# M55M1 register map
File version: 1.0
Registers are 32-bit, read-write, reset 0x0 unless marked. A register's access mark holds for its fields unless they carry their own. Offsets are from the block's base; [hi:lo] are bit positions; lines under a group give offsets from that group; {n}, {i} and the like mark numbered series; 'fields as' and 'values as' point back to an identical list.

## PMC — PMC Register Map
Base 0x40002000
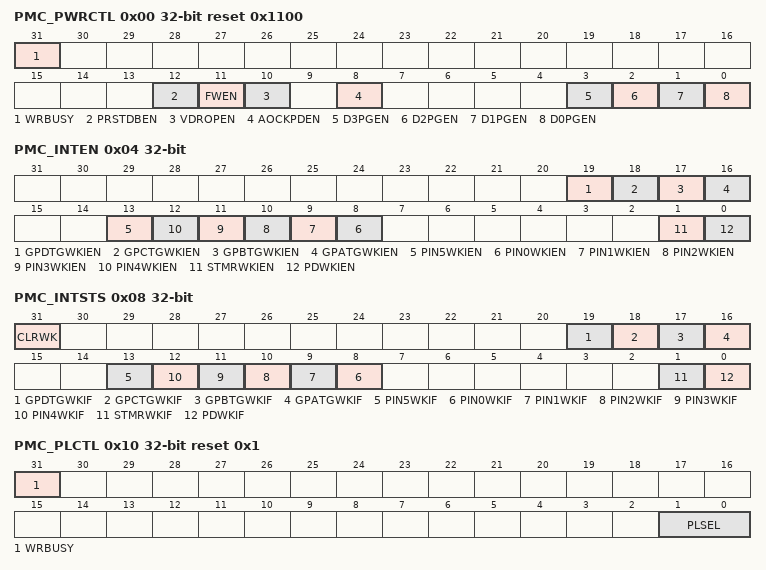
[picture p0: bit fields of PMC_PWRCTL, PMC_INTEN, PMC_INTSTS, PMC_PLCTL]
0x00 PMC_PWRCTL reset 0x1100 — System Power-down Control Register
  [31] WRBUSY ro — Write Busy Flag (Read Only). If PMC_PWRCTL is written, this bit is asserted automatically by hardware, and is de-asserted when write procedure is finished.
    0=PMC_PWRCTL register is ready for write operation; 1=PMC_PWRCTL register is busy on the last write operation. Other write operations are ignored
  [12] PRSTDBEN — Pin Reset De-Bounce Enable Bit (Write Protect). When this bit is set to 1, pin reset clock base de-bounce circuit is enable in Power-down mode. Note 1: This bit is write protected. Refer to the SYS_REGLCTL register. Note 2: This bit is not retained when D2 power is turned off. Note 3: If D2PGEN(PMC_PWRCTL[2]) is 1, The pin reset de-bounce circuit always keep disable, even if PRSTDBEN is 1. Note 4: If VDROPEN(PMC_PWRCTL[10]) is 1, The pin reset de-bounce circuit always keep disable, even if PRSTDBEN is 1.
    0=Pin reset de-bounce circuit Disable, and de-bounce time about 300ns; 1=Pin reset de-bounce circuit Enable, and de-bounce time about 32us
  [11] FWEN — Fast Wake-up Enable Bit (Write Protect). When this bit is set to 1, wake-up will be speed up, but power consumption is increase about 30uA in Power-down mode. Note 1: This bit is write protected. Refer to the SYS_REGLCTL register. Note 2: Write operation is ignored when WRBUSY is high. Note 3: This bit is not retained when D4 power is turned off.
    0=Regulator voltage auto drop function Disabled; 1=Regulator voltage auto drop function Enabled
  [10] VDROPEN — Voltage Regulator Output Drop Enable Bit (Write Protect). When this bit is set to 1, voltage regulator output drop to 0.7v in Power-down mode. Note 1: This bit is write protected. Refer to the SYS_REGLCTL register. Note 2: Write operation is ignored when WRBUSY is high. Note 3: This bit is not retained when D3 power is turned off.
    values as FWEN
  [8] AOCKPDEN — Auto Operation Mode Clock Power-down Enable (Write Protect). When this bit is set to 1, Auto Operation Mode clock Power-down mode is enabled and MIRC and HIRC keeps active till the chip enter Power-down mode. If chip in Power-down mode, HXT, HIRC48M, APLL0, APLL1 and system clock will be disabled and ignored the clock source selection. The clocks of peripheral are not controlled by Power-down mode, if the peripheral clock source is from LXT, LIRC, MIRC or HIRC. Note 1: This bit is write protected. Refer to the SYS_REGLCTL register. Note 2: This bit is not retained when D2 power is turned off.
    0=MIRC and HIRC enable in Power-down mode; 1=MIRC and HIRC disable in Power-down mode under normal circumstances, but MIRC and HIRC will be enable via a trigger from auto operation mode
  [3] D3PGEN — Power Domain 3 Power Gating Enable Bit (Write Protect). This bit control power domain 3 (Standby Power Domain) power gating function when system enter Power-down mode(CPU execute WFI/WFE instruction and SLEEPDEEP(SCR[2]) is 1). Note 1: This bit is write protected. Refer to the SYS_REGLCTL register. Note 2: Write operation is ignored when WRBUSY is high. Note 3: If D2PGEN(PMC_PWRCTL[2]) is 0, The power domain 3 always keep supply, even if D3PGEN is 1. Note 4: This bit is not retained when D4 power is turned off.
    0=Power domain 3 keep supply; 1=Power domain 3 stop supply
  [2] D2PGEN — Power Domain 2 Power Gating Enable Bit (Write Protect). This bit control power domain 2 (Low Power Domain) power gating function when system enter Power-down mode(CPU execute WFI/WFE instruction and SLEEPDEEP(SCR[2]) is 1). Note 1: This bit is write protected. Refer to the SYS_REGLCTL register. Note 2: Write operation is ignored when WRBUSY is high. Note 3: If D1PGEN(PMC_PWRCTL[1]) is 0, The power domain 2 always keep supply, even if D2PGEN is 1. Note 4: This bit is not retained when D4 power is turned off.
    0=Power domain 2 keep supply; 1=Power domain 2 stop supply
  [1] D1PGEN — Power Domain 1 Power Gating Enable Bit (Write Protect). This bit control power domain 1 (Base Domain) power gating function when system enter Power-down mode(CPU execute WFI/WFE instruction and SLEEPDEEP(SCR[2]) is 1). Note 1: This bit is write protected. Refer to the SYS_REGLCTL register. Note 2: Write operation is ignored when WRBUSY is high. Note 3: If D0PGEN(PMC_PWRCTL[0]) is 0, The power domain 1 always keep supply, even if D1PGEN is 1. Note 4: This bit is not retained when D4 power is turned off.
    0=Power domain 1 keep supply; 1=Power domain 1 stop supply
  [0] D0PGEN — Power Domain 0 Power Gating Enable Bit (Write Protect). This bit control power domain 0 (Performance Domain) power gating function when system enter Power-down mode(CPU execute WFI/WFE instruction and SLEEPDEEP(SCR[2]) is 1). Note 1: This bit is write protected. Refer to the SYS_REGLCTL register. Note 2: Write operation is ignored when WRBUSY is high. Note 3: This bit is not retained when D4 power is turned off.
    0=Power domain 0 keep supply; 1=Power domain 0 stop supply
0x04 PMC_INTEN — PMC Interrupt Enable Register
  [19] GPDTGWKIEN — GPD Trigger Wake-up Interrupt Enable Bit (Write Protect). Note 1: The PMC interrupt will occur when both GPDTGWKIF(PMC_INTSTS[19] and GPDTGWKIEN(PMC_INTEN[19]) are 1. Note 2: This bit is write protected. Refer to the SYS_REGLCTL register. Note 3: This bit is not retained when D3 power is turned off.
    0=GPD triggrer wake-up interrupt disabled; 1=GPD triggrer wake-up interrupt enabled
  [18] GPCTGWKIEN — GPC Trigger Wake-up Interrupt Enable Bit (Write Protect). Note 1: The PMC interrupt will occur when both GPCTGWKIF(PMC_INTSTS[18] and GPCTGWKIEN(PMC_INTEN[18]) are 1. Note 2: This bit is write protected. Refer to the SYS_REGLCTL register. Note 3: This bit is not retained when D3 power is turned off.
    0=GPC triggrer wake-up interrupt disabled; 1=GPC triggrer wake-up interrupt enabled
  [17] GPBTGWKIEN — GPB Trigger Wake-up Interrupt Enable Bit (Write Protect). Note 1: The PMC interrupt will occur when both GPBTGWKIF(PMC_INTSTS[17] and GPBTGWKIEN(PMC_INTEN[17]) are 1. Note 2: This bit is write protected. Refer to the SYS_REGLCTL register. Note 3: This bit is not retained when D3 power is turned off.
    0=GPB triggrer wake-up interrupt disabled; 1=GPB triggrer wake-up interrupt enabled
  [16] GPATGWKIEN — GPA Trigger Wake-up Interrupt Enable Bit (Write Protect). Note 1: The PMC interrupt will occur when both GPATGWKIF(PMC_INTSTS[16] and GPATGWKIEN(PMC_INTEN[16]) are 1. Note 2: This bit is write protected. Refer to the SYS_REGLCTL register. Note 3: This bit is not retained when D3 power is turned off.
    0=GPA triggrer wake-up interrupt disabled; 1=GPA triggrer wake-up interrupt enabled
  [13] PIN5WKIEN — Pin 5 Wake-up Interrupt Enable Bit (Write Protect). Note 1: The PMC interrupt will occur when both PIN4WKIF(PMC_INTSTS[13] and PIN4WKIEN(PMC_INTEN[13]) are 1. Note 2: This bit is write protected. Refer to the SYS_REGLCTL register. Note 3: This bit is not retained when D4 power is turned off.
    0=Pin 5 wake-up interrupt disabled; 1=Pin 5 wake-up interrupt enabled
  [n+8] PIN{n}WKIEN (n=0..4) — Pin {n} Wake-up Interrupt Enable Bit (Write Protect). Note 1: The PMC interrupt will occur when both PIN{n}WKIF(PMC_INTSTS[{n+8}] and PIN{n}WKIEN(PMC_INTEN[{n+8}]) are 1. Note 2: This bit is write protected. Refer to the SYS_REGLCTL register. Note 3: This bit is not retained when D4 power is turned off.
    0=Pin {n} wake-up interrupt disabled; 1=Pin {n} wake-up interrupt enabled
  [1] STMRWKIEN — Standby Timer Wake-up Interrupt Enable Bit (Write Protect). Note 1: The PMC interrupt will occur when both STMRWKIF(PMC_INTSTS[1] and STMRWKIEN(PMC_INTEN[1]) are 1. Note 2: This bit is write protected. Refer to the SYS_REGLCTL register. Note 3: This bit is not retained when D4 power is turned off.
    0=High Voltage Timer wake-up interrupt disable; 1=High Voltage Timer wake-up interrupt enabled
  [0] PDWKIEN — Power-down Mode Wake-up Interrupt Enable Bit (Write Protect). Note 1: The PMC interrupt will occur when both PDWKIF(PMC_INTSTS[0] and PDWKIEN(PMC_INTEN[0]) are 1. Note 2: This bit is write protected. Refer to the SYS_REGLCTL register. Note 3: This bit is not retained when D4 power is turned off.
    0=Power-down mode wake-up interrupt Disabled; 1=Power-down mode wake-up interrupt Enabled
0x08 PMC_INTSTS — PMC Interrupt Status Register
  [31] CLRWK — Clear Wake-up Flag. Clearing the Wake-up flag is not timely. Flags in PMC_INTSTS will not be immediately cleared in the next cycle when CLRWK written to 1. Note 1: This bit is auto cleared by hardware.
    0=No clear; 1=Clear all wake-up flags
  [19] GPDTGWKIF — GPC Trigger Wake-up Interrupt Status. The flag is set if GPD trigger wake-up event occurred in Power-down mode. Note 1: The PMC interrupt will occur when both GPDTGWKIF(PMC_INTSTS[19] and GPDTGWKIEN(PMC_INTEN[19]) are 1. Note 2: This bit is not retained when D0 power is turned off.
  [18] GPCTGWKIF — GPC Trigger Wake-up Interrupt Status. The flag is set if GPC trigger wake-up event occurred in Power-down mode. Note 1: The PMC interrupt will occur when both GPCTGWKIF(PMC_INTSTS[18] and GPCTGWKIEN(PMC_INTEN[18]) are 1. Note 2: This bit is not retained when D0 power is turned off.
  [17] GPBTGWKIF — GPB Trigger Wake-up Interrupt Status. The flag is set if GPB trigger wake-up event occurred in Power-down mode. Note 1: The PMC interrupt will occur when both GPBTGWKIF(PMC_INTSTS[17] and GPBTGWKIEN(PMC_INTEN[17]) are 1. Note 2: This bit is not retained when D0 power is turned off.
  [16] GPATGWKIF — GPA Trigger Wake-up Interrupt Status. The flag is set if GPA trigger wake-up event occurred in Power-down mode. Note 1: The PMC interrupt will occur when both GPATGWKIF(PMC_INTSTS[16] and GPATGWKIEN(PMC_INTEN[16]) are 1. Note 2: This bit is not retained when D0 power is turned off.
  [13] PIN5WKIF — Pin 5 Wake-up Interrupt Status. The flag is set if Pin 5 wake-up event occurred in Power-down mode. Note 1: The PMC interrupt will occur when both PIN4WKIF(PMC_INTSTS[13] and PIN4WKIEN(PMC_INTEN[13]) are 1. Note 2: This bit is not retained when D0 power is turned off.
  [n+8] PIN{n}WKIF (n=0..4) — Pin {n} Wake-up Interrupt Status. The flag is set if Pin {n} wake-up event occurred in Power-down mode. Note 1: The PMC interrupt will occur when both PIN{n}WKIF(PMC_INTSTS[{n+8}] and PIN{n}WKIEN(PMC_INTEN[{n+8}]) are 1. Note 2: This bit is not retained when D0 power is turned off.
  [1] STMRWKIF — Standby Timer Wake-up Interrupt Status. The flag is set if stadnby timer wake-up event occurred in Power-down mode. Note 1: The PMC interrupt will occur when both STMRWKIF(PMC_INTSTS[1] and STMRWKIEN(PMC_INTEN[1]) are 1. Note 2: This bit is not retained when D0 power is turned off.
  [0] PDWKIF — Power-down Mode Wake-up Interrupt Status. Set by 'Power-down wake-up event', it indicates that resume from Power-down mode. The flag is set if any wake-up source occurred. Refer Power Modes and Wake-up Sources chapter. Note 1: The PMC interrupt will occur when both PDWKIF(PMC_INTSTS[0] and PDWKIEN(PMC_INTEN[0]) are 1. Note 2: This bit is not retained when D0 power is turned off.
0x10 PMC_PLCTL reset 0x1 — Power Level Control Register
  [31] WRBUSY ro — Write Busy Flag (Read Only). If PMC_PLCTL is written, this bit is asserted automatically by hardware, and is de-asserted when write procedure is finished.
    0=PMC_PLCTL register is ready for write operation; 1=PMC_PLCTL register is busy on the last write operation. Other write operations are ignored
  [1:0] PLSEL — Power Level Select (Write Protect). Note 1: These bits are write protected. Refer to the SYS_REGLCTL register. Note 2: Write operation is ignored when WRBUSY is high. Note 3: These bits are not retained when D3 power is turned off.
    0=Set to Power level 0 (PL0); 1=Set to Power level 1 (PL1). (default)
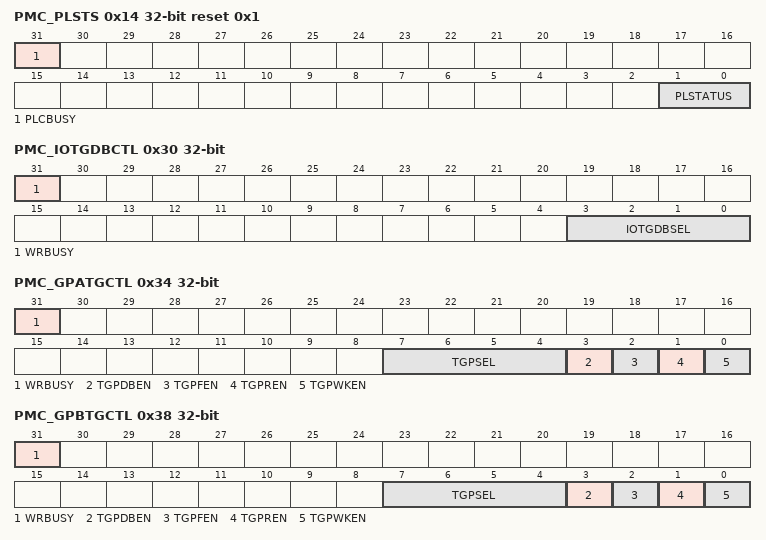
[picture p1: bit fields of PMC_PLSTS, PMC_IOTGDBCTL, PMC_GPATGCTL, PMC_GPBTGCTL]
0x14 PMC_PLSTS reset 0x1 — Power Level Status Register
  [31] PLCBUSY ro — Power Level Change Busy Bit (Read Only). This bit is set by hardware when power level is changing. After power level change is completed, this bit will be cleared automatically by hardware.
    0=Power level change is completed; 1=Power level change is ongoing
  [1:0] PLSTATUS ro — Power Level Status (Read Only). This bit field reflect the current power level.
    0=Power level is PL0; 1=Power level is PL1
0x20 PMC_IOSHCTL — GPIO Status Hold Control Register
  [0] IOHR — GPIO Hold Release. Note 1: This bit is auto cleared by hardware. Note 2: This bit is not retained when D0 power is turned off.
0x28 PMC_BATLDCTL — Battery Loss Detector Control Register
  [0] BATLDEN — Battery Loss Detector Enable Bit (Write Protect). Note 1: This bit is write protected. Refer to the SYS_REGLCTL register. Note 2: This bit is not retained when D3 power is turned off.
    0=Battery Loss Detector Disabled; 1=Battery Loss Detector Enabled
0x30 PMC_IOTGDBCTL — GPIO Trigger De-bounce Control Register
  [31] WRBUSY ro — Write Busy Flag (Read Only). If PMC_IOTGDBCTL is written, this bit is asserted automatically by hardware, and is de-asserted when write procedure is finished.
    0=PMC_ IOTGDBCTL register is ready for write operation; 1=PMC_ IOTGDBCTL register is busy on the last write operation. Other write operations are ignored
  [3:0] IOTGDBSEL — GPIO Trigger Pin De-bounce Sampling Cycle Selection. Note 1: De-bounce counter clock source is the 32 kHz internal low speed RC oscillator (LIRC). Note 2: Write operation is ignored when WRBUSY is high. Note 3: These bits are not retained when D3 power is turned off.
    0=Sample GPIO input once per 1 clock; 1=Sample GPIO input once per 2 clocks; 2=Sample GPIO input once per 4 clocks; 3=Sample GPIO input once per 8 clocks; 4=Sample GPIO input once per 16 clocks; 5=Sample GPIO input once per 32 clocks; 6=Sample GPIO input once per 64 clocks; 7=Sample GPIO input once per 128 clocks; 8=Sample GPIO input once per 256 clocks; 9=Sample GPIO input once per 2*256 clocks; 10=Sample GPIO input once per 4*256 clocks; 11=Sample GPIO input once per 8*256 clocks; 12=Sample GPIO input once per 16*256 clocks; 13=Sample GPIO input once per 32*256 clocks; 14=Sample GPIO input once per 64*256 clocks; 15=Sample GPIO input once per 128*256 clocks
0x34 PMC_GPATGCTL — GPA Trigger Control Register
  [31] WRBUSY ro — Write Busy Flag (Read Only). If PMC_GPATGCTL is written, this bit is asserted automatically by hardware, and is de-asserted when write procedure is finished.
    0=PMC_ GPATGCTL register is ready for write operation; 1=PMC_ GPATGCTL register is busy on the last write operation. Other write operations are ignored
  [7:4] TGPSEL — GPA Trigger Pin Select. Note: These bits are not retained when D3 power is turned off.
    0=GPA.0 trigger function Enabled; 1=GPA.1 trigger function Enabled; 2=GPA.2 trigger function Enabled; 3=GPA.3 trigger function Enabled; 4=GPA.4 trigger function Enabled; 5=GPA.5 trigger function Enabled; 6=GPA.6 trigger function Enabled; 7=GPA.7 trigger function Enabled; 8=GPA.8 trigger function Enabled; 9=GPA.9 trigger function Enabled; 10=GPA.10 trigger function Enabled; 11=GPA.11 trigger function Enabled; 12=GPA.12 trigger function Enabled; 13=GPA.13 trigger function Enabled; 14=GPA.14 trigger function Enabled; 15=GPA.15 trigger function Enabled
  [3] TGPDBEN — GPA Trigger Pin Input Signal De-bounce Enable Bit. The DBEN bit is used to enable the de-bounce function for each corresponding I/O. If the input signal pulse width cannot be sampled by continuous two de-bounce sample cycle, the input signal transition is seen as the signal bounce and will not trigger and wake-up.The de-bounce clock source is the 32 kHz internal low speed RC oscillator (LIRC). Note 1: The 32 kHz internal low speed RC oscillator (LIRC) will automatically be enabled if TGPDBEN is 1. Note 2: Write operation is ignored when WRBUSY is high. Note 3: This bit is not retained when D3 power is turned off.
    0=Trigger pin De-bounce function Disabled; 1=Trigger pin De-bounce function Enabled
  [2] TGPFEN — GPA Trigge Pin Falling Edge Enable Bit. Note 1: Write operation is ignored when WRBUSY is high. Note 2: This bit is not retained when D3 power is turned off.
    0=GPA group trigger pin falling edge trigger function Disabled; 1=GPA group trigger pin falling edge trigger function Enabled
  [1] TGPREN — GPA Trigger Pin Rising Edge Enable Bit. Note 1: Write operation is ignored when WRBUSY is high. Note 2: This bit is not retained when D3 power is turned off.
    0=GPA group trigger pin rising edge trigger function Disabled; 1=GPA group trigger pin rising edge trigger function Enabled
  [0] TGPWKEN — GPA Trigger Pin Wake-up Enable Bit. Note 1: The GPA Trigger Pin wake-up is always enable when D2PGEN(PMC_PWRCTL[2] is 1. Note 2: This bit is not retained when D2 power is turned off.
    0=GPA group trigger pin wake-up chip Disabled, trigger ip Enabled; 1=GPA group trigger pin wake-up chip Enabled, trigger ip Enabled
0x38 PMC_GPBTGCTL — GPB Trigger Control Register
  [31] WRBUSY ro — Write Busy Flag (Read Only). If PMC_GPBTGCTL is written, this bit is asserted automatically by hardware, and is de-asserted when write procedure is finished.
    0=PMC_ GPBTGCTL register is ready for write operation; 1=PMC_ GPBTGCTL register is busy on the last write operation. Other write operations are ignored
  [7:4] TGPSEL — GPB Trigger Pin Select. Note: These bits are not retained when D3 power is turned off.
    0=GPB.0 trigger function Enabled; 1=GPB.1 trigger function Enabled; 2=GPB.2 trigger function Enabled; 3=GPB.3 trigger function Enabled; 4=GPB.4 trigger function Enabled; 5=GPB.5 trigger function Enabled; 6=GPB.6 trigger function Enabled; 7=GPB.7 trigger function Enabled; 8=GPB.8 trigger function Enabled; 9=GPB.9 trigger function Enabled; 10=GPB.10 trigger function Enabled; 11=GPB.11 trigger function Enabled; 12=GPB.12 trigger function Enabled; 13=GPB.13 trigger function Enabled; 14=GPB.14 trigger function Enabled; 15=GPB.15 trigger function Enabled
  [3] TGPDBEN — GPB Trigger Pin Input Signal De-bounce Enable Bit. The DBEN bit is used to enable the de-bounce function for each corresponding I/O. If the input signal pulse width cannot be sampled by continuous two de-bounce sample cycle, the input signal transition is seen as the signal bounce and will not trigger and wake-up.The de-bounce clock source is the 32 kHz internal low speed RC oscillator (LIRC). Note 1: The 32 kHz internal low speed RC oscillator (LIRC) will automatically be enabled if TGPDBEN is 1. Note 2: Write operation is ignored when WRBUSY is high. Note 3: This bit is not retained when D3 power is turned off.
    values as PMC_GPATGCTL.TGPDBEN
  [2] TGPFEN — GPB Trigge Pin Falling Edge Enable Bit. Note: This bit is not retained when D3 power is turned off.
    0=GPB group trigger pin falling edge trigger function Disabled; 1=GPB group trigger pin falling edge trigger function Enabled
  [1] TGPREN — GPB Trigger Pin Rising Edge Enable Bit. Note 1: Write operation is ignored when WRBUSY is high. Note 2: This bit is not retained when D3 power is turned off.
    0=GPB group trigger pin rising edge trigger function Disabled; 1=GPB group trigger pin rising edge trigger function Enabled
  [0] TGPWKEN — GPB Trigger Pin Wake-up Enable Bit. Note 1: The GPB Trigger Pin wake-up is always enable when D2PGEN(PMC_PWRCTL[2] is 1. Note 2: This bit is not retained when D2 power is turned off.
    0=GPB group trigger pin wake-up chip Disabled, trigger ip Enabled; 1=GPB group trigger pin wake-up chip Enabled, trigger ip Enabled
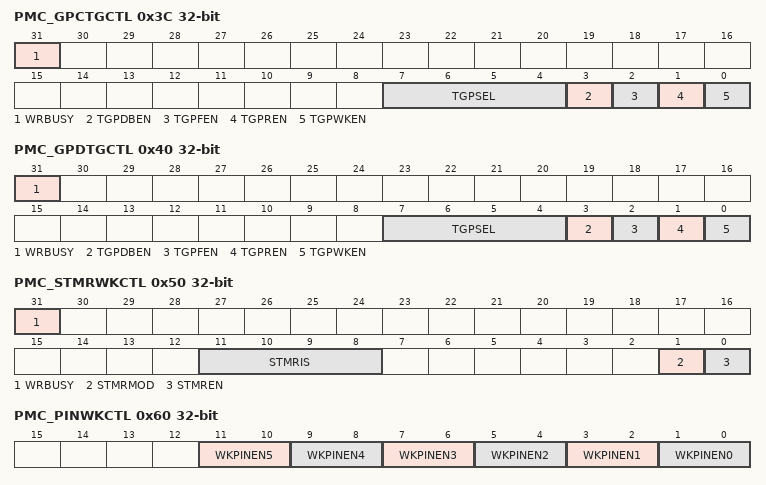
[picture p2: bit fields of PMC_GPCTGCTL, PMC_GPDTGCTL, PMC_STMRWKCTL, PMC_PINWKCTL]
0x3C PMC_GPCTGCTL — GPC Trigger Control Register
  [31] WRBUSY ro — Write Busy Flag (Read Only). If PMC_GPCTGCTL is written, this bit is asserted automatically by hardware, and is de-asserted when write procedure is finished.
    0=PMC_ GPCTGCTL register is ready for write operation; 1=PMC_ GPCTGCTL register is busy on the last write operation. Other write operations are ignored
  [7:4] TGPSEL — GPC Trigger Pin Select. Note: These bits are not retained when D3 power is turned off.
    0=GPC.0 trigger function Enabled; 1=GPC.1 trigger function Enabled; 2=GPC.2 trigger function Enabled; 3=GPC.3 trigger function Enabled; 4=GPC.4 trigger function Enabled; 5=GPC.5 trigger function Enabled; 6=GPC.6 trigger function Enabled; 7=GPC.7 trigger function Enabled; 8=GPC.8 trigger function Enabled; 9=GPC.9 trigger function Enabled; 10=GPC.10 trigger function Enabled; 11=GPC.11 trigger function Enabled; 12=GPC.12 trigger function Enabled; 13=GPC.13 trigger function Enabled; 14=GPC.14 trigger function Enabled
  [3] TGPDBEN — GPC Trigger Pin Input Signal De-bounce Enable Bit. The TGPDBEN bit is used to enable the de-bounce function for each corresponding I/O. If the input signal pulse width cannot be sampled by continuous two de-bounce sample cycle, the input signal transition is seen as the signal bounce and will not trigger and wake-up.The de-bounce clock source is the 32 kHz internal low speed RC oscillator (LIRC). Note 1: The 32 kHz internal low speed RC oscillator (LIRC) will automatically be enabled if TGPDBEN is 1. Note 2: Write operation is ignored when WRBUSY is high. Note 3: This bit is not retained when D3 power is turned off.
    values as PMC_GPATGCTL.TGPDBEN
  [2] TGPFEN — GPC Trigge Pin Falling Edge Enable Bit. Note 1: Write operation is ignored when WRBUSY is high. Note 2: This bit is not retained when D3 power is turned off.
    0=GPC group trigger pin falling edge trigger function Disabled; 1=GPC group trigger pin falling edge trigger function Enabled
  [1] TGPREN — GPC Trigger Pin Rising Edge Enable Bit. Note 1: Write operation is ignored when WRBUSY is high. Note 2: This bit is not retained when D3 power is turned off.
    0=GPC group trigger pin rising edge trigger function Disabled; 1=GPC group trigger pin rising edge trigger function Enabled
  [0] TGPWKEN — GPC Trigger Pin Wake-up Enable Bit. Note 1: The GPC Trigger Pin wake-up is always enable when D2PGEN(PMC_PWRCTL[2] is 1. Note 2: This bit is not retained when D2 power is turned off.
    0=GPC group trigger pin wake-up chip Disabled, trigger ip Enabled; 1=GPC group trigger pin wake-up chip Enabled, trigger ip Enabled
0x40 PMC_GPDTGCTL — GPD Trigger Control Register
  [31] WRBUSY ro — Write Busy Flag (Read Only). If PMC_GPDTGCTL is written, this bit is asserted automatically by hardware, and is de-asserted when write procedure is finished.
    0=PMC_ GPDTGCTL register is ready for write operation; 1=PMC_ GPDTGCTL register is busy on the last write operation. Other write operations are ignored
  [7:4] TGPSEL — GPD Trigger Pin Select. Note: These bits are not retained when D3 power is turned off.
    0=GPD.0 trigger function Enabled; 1=GPD.1 trigger function Enabled; 2=GPD.2 trigger function Enabled; 3=GPD.3 trigger function Enabled; 4=GPD.4 trigger function Enabled; 5=GPD.5 trigger function Enabled; 6=GPD.6 trigger function Enabled; 7=GPD.7 trigger function Enabled; 8=GPD.8 trigger function Enabled; 9=GPD.9 trigger function Enabled; 10=GPD.10 trigger function Enabled; 11=GPD.11 trigger function Enabled; 12=GPD.12 trigger function Enabled; 13=GPD.13 trigger function Enabled; 14=GPD.14 trigger function Enabled
  [3] TGPDBEN — GPD Trigger Pin Input Signal De-bounce Enable Bit. The DBEN bit is used to enable the de-bounce function for each corresponding I/O. If the input signal pulse width cannot be sampled by continuous two de-bounce sample cycle, the input signal transition is seen as the signal bounce and will not trigger and wake-up.The de-bounce clock source is the 32 kHz internal low speed RC oscillator (LIRC). Note 1: The 32 kHz internal low speed RC oscillator (LIRC) will automatically be enabled if TGPDBEN is 1. Note 2: Write operation is ignored when WRBUSY is high. Note 3: This bit is not retained when D3 power is turned off.
    values as PMC_GPATGCTL.TGPDBEN
  [2] TGPFEN — GPD Trigge Pin Falling Edge Enable Bit. Note 1: Write operation is ignored when WRBUSY is high. Note 2: This bit is not retained when D3 power is turned off.
    0=GPD group trigger pin falling edge trigger function Disabled; 1=GPD group trigger pin falling edge trigger function Enabled
  [1] TGPREN — GPD Trigger Pin Rising Edge Enable Bit. Note 1: Write operation is ignored when WRBUSY is high. Note 2: This bit is not retained when D3 power is turned off.
    0=GPD group trigger pin rising edge trigger function Disabled; 1=GPD group trigger pin rising edge trigger function Enabled
  [0] TGPWKEN — GPD Trigger Pin Wake-up Enable Bit. Note 1: The GPD Trigger Pin wake-up is always enable when D2PGEN(PMC_PWRCTL[2] is 1. Note 2: This bit is not retained when D2 power is turned off.
    0=GPD group trigger pin wake-up chip Disabled, trigger ip Enabled; 1=GPD group trigger pin wake-up chip Enabled, trigger ip Enabled
0x50 PMC_STMRWKCTL — Standby Timer Wake-up Control Register
  [31] WRBUSY ro — Write Busy Flag (Read Only). If PMC_STMRWKCTL is written, this bit is asserted automatically by hardware, and is de-asserted when write procedure is finished.
    0=PMC_ STMRWKCTL register is ready for write operation; 1=PMC_ STMRWKCTL register is busy on the last write operation. Other write operations are ignored
  [11:8] STMRIS — Stadnby Timer Time-out Interval Select (Write Protect). These bits control standby timer time-out interval when chip at Power-down mode. Note 1: These bits are write protected. Refer to the SYS_REGLCTL register. Note 2: Write operation is ignored when WRBUSY is high. Note 3: These bits are not retained when D4 power is turned off.
    0=Time-out interval is 512 LIRC clocks (16ms); 1=Time-out interval is 1024 LIRC clocks (32ms); 2=Time-out interval is 2048 LIRC clocks (64ms); 3=Time-out interval is 4096 LIRC clocks (128ms); 4=Time-out interval is 8192 LIRC clocks (256ms); 5=Time-out interval is 16384 LIRC clocks (512ms); 6=Time-out interval is 32768 LIRC clocks (1024ms); 7=Time-out interval is 65536 LIRC clocks (2048ms); 8=Time-out interval is 131072 LIRC clocks (4096ms); 9=Time-out interval is 262144 LIRC clocks (8192ms); 10=Time-out interval is 524288 LIRC clocks (16384ms); 11=Time-out interval is 1048576 LIRC clocks (32768ms); 12=Time-out interval is 2097152 LIRC clocks (65536ms); 13=Time-out interval is 4194304 LIRC clocks (131072ms)
  [1] STMRMOD — Standby Timer Mode (Write Protect). Note 1: This bit is write protected. Refer to the SYS_REGLCTL register. Note 2: Write operation is ignored when WRBUSY is high. Note 3: This bit is not retained when D4 power is turned off.
    0=Standby timer start when enter any of Power-down mode ( except CPU idle mode); 1=Standby timer start immedially when STMREN (PMC_STMRWKCTL[0]) =1
  [0] STMREN — Standby Timer Enable Bit (Write Protect). Note 1: This bit is write protected. Refer to the SYS_REGLCTL register. Note 2: Write operation is ignored when WRBUSY is high. Note 3: This bit is not retained when D4 power is turned off.
    0=Standby timer disabled; 1=Standby timer Enabled
0x60 PMC_PINWKCTL — Pin Wake-up Control Register
  [all] fields
    0=Wake-up pin disable; 1=Wake-up pin rising edge enabled; 2=Wake-up pin falling edge enabled; 3=Wake-up pin both edge enabled
  [11:10] WKPINEN5 — Wake-up Pin5 Enable Bit (Write Protect). This is control register for GPA.12 to wake-up pin. Note 1: These bits are write protected. Refer to the SYS_REGLCTL register. Note 2: These bits are not retained when D4 power is turned off.
  [9:8] WKPINEN4 — Wake-up Pin4 Enable Bit (Write Protect). This is control register for GPF.6 to wake-up pin. Note 1: These bits are write protected. Refer to the SYS_REGLCTL register. Note 2: These bits are not retained when D4 power is turned off. Note 3: Setting IOCTLSEL(RTC_LXTCTL[8]) to avoid GPF6 unexpected falling edge.
  [7:6] WKPINEN3 — Wake-up Pin3 Enable Bit (Write Protect). This is control register for GPB.12 to wake-up pin. Note 1: These bits are write protected. Refer to the SYS_REGLCTL register. Note 2: These bits are not retained when D4 power is turned off.
  [5:4] WKPINEN2 — Wake-up Pin2 Enable Bit (Write Protect). This is control register for GPB.2 to wake-up pin. Note 1: These bits are write protected. Refer to the SYS_REGLCTL register. Note 2: These bits are not retained when D4 power is turned off.
  [3:2] WKPINEN1 — Wake-up Pin1 Enable Bit (Write Protect). This is control register for GPB.0 to wake-up pin. Note 1: These bits are write protected. Refer to the SYS_REGLCTL register. Note 2: These bits are not retained when D4 power is turned off.
  [1:0] WKPINEN0 — Wake-up Pin0 Enable Bit (Write Protect). This is control register for GPC.0 to wake-up pin. Note 1: These bits are write protected. Refer to the SYS_REGLCTL register. Note 2: These bits are not retained when D4 power is turned off.
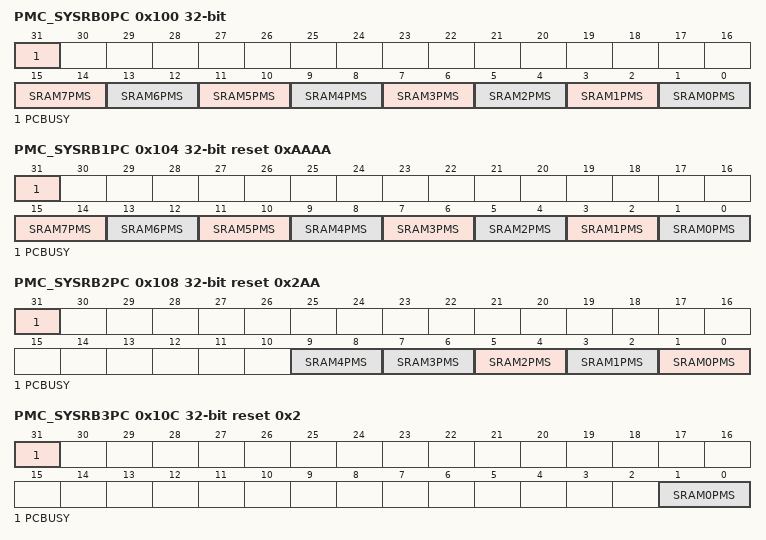
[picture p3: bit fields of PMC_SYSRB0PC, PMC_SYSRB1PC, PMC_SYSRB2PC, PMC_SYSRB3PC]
0x100 PMC_SYSRB0PC — System SRAM Bank 0 Power Mode Control Register
  [31] PCBUSY ro — Power Changing Busy Flag (Read Only). If PMC_SYSRB0PC is written, this bit is asserted automatically by hardware, and is de-asserted when SRAM power change procedure is finished. set to power shut down mode by hardware. Note 1: This bit is not retained when D3 power is turned off.
    0=System SRAM bank 0 power change finished; 1=System SRAM bank 0 power changing. The PMC_SYSRB0PC write operations are ignored
  [2n+1:2n] SRAM{n}PMS (n=0..7) — System SRAM{n} In Bank0 Power Mode Select (Write Protect). This field can control SRAM{n} in bank0 (64k) power mode for range {0x2010+n}_0000 - {0x2010+n}_FFFF. Note 1: Power shut down mode can get least leakage, but don't guarantee the retention of SRAM data. Note 2: This bit is write protected. Refer to the SYS_REGLCTL register. Note 3: Write operation is ignored when PCBUSY is 1. Note 4: These bits are not retained when D3 power is turned off.
    0=System SRAM{n} in bank0 is normal mode; 1=System SRAM{n} in bank0 is retention mode; 2=System SRAM{n} in bank0 is power shut down mode
0x104 PMC_SYSRB1PC reset 0xAAAA — System SRAM Bank 1 Power Mode Control Register
  [31] PCBUSY ro — Power Changing Busy Flag (Read Only). If PMC_SYSRB1PC is written, this bit is asserted automatically by hardware, and is de-asserted when SRAM power change procedure is finished. Note 1: This bit is not retained when D0 power is turned off.
    0=System SRAM bank 1 power change finished; 1=System SRAM bank 1 power changing. The PMC_SYSRB1PC write operations are ignored
  [2n+1:2n] SRAM{n}PMS (n=0..7) — System SRAM{n} In Bank1 Power Mode Select (Write Protect). This field can control SRAM{n} in bank1 (64k) power mode for range {0x2018+n}_0000 - {0x2018+n}_FFFF. Note 1: Power shut down mode can get least leakage, but don't guarantee the retention of SRAM data. Note 2: This bit is write protected. Refer to the SYS_REGLCTL register. Note 3: Write operation is ignored when PCBUSY is 1. Note 4: If system enter Power-down mode and D0PGEN(PMC_PWRCTL[0]) is set to 1, This SRAM is auto set to power shut down mode by hardware. Note 5: These bits are not retained when D0 power is turned off.
    0=System SRAM{n} in bank1 is normal mode; 1=System SRAM{n} in bank1 is retention mode; 2=System SRAM{n} in bank1 is power shut down mode
0x108 PMC_SYSRB2PC reset 0x2AA — System SRAM Bank 2 Power Mode Control Register
  [31] PCBUSY ro — Power Changing Busy Flag (Read Only). If PMC_SYSRB2PC is written, this bit is asserted automatically by hardware, and is de-asserted when SRAM power change procedure is finished. Note: This bit is not retained when D0 power is turned off.
    0=System SRAM bank 2 power change finished; 1=System SRAM bank 2 power changing. The PMC_SYSRB2PC write operations are ignored
  [9:8] SRAM4PMS — System SRAM4 In Bank2 Power Mode Select (Write Protect). This field can control SRAM2 in bank1 (64k) power mode for range 0x2024_0000 - 0x2024_FFFF. Note 1: Power shut down mode can get least leakage, but don't guarantee the retention of SRAM data. Note 2: This bit is write protected. Refer to the SYS_REGLCTL register. Note 3: Write operation is ignored when PCBUSY is 1. Note 4: If system enter Power-down mode and D0PGEN(PMC_PWRCTL[0]) is set to 1, This SRAM is auto set to power shut down mode by hardware. Note 5: These bits are not retained when D0 power is turned off.
    0=System SRAM4 in bank2 is normal mode; 1=System SRAM4 in bank2 is retention mode; 2=System SRAM4 in bank2 is power shut down mode
  [2n+1:2n] SRAM{n}PMS (n=0..3) — System SRAM{n} In Bank2 Power Mode Select (Write Protect). This field can control SRAM{n} in bank2 (64k) power mode for range {0x2020+n}_0000 - {0x2020+n}_FFFF. Note 1: Power shut down mode can get least leakage, but don't guarantee the retention of SRAM data. Note 2: This bit is write protected. Refer to the SYS_REGLCTL register. Note 3: Write operation is ignored when PCBUSY is 1. Note 4: If system enter Power-down mode and D0PGEN(PMC_PWRCTL[0]) is set to 1, This SRAM is auto set to power shut down mode by hardware. Note 5: These bits are not retained when D0 power is turned off.
    0=System SRAM{n} in bank2 is normal mode; 1=System SRAM{n} in bank2 is retention mode; 2=System SRAM{n} in bank2 is power shut down mode
0x10C PMC_SYSRB3PC reset 0x2 — System SRAM Bank 3 Power Mode Control Register
  [31] PCBUSY ro — Power Changing Busy Flag (Read Only). If PMC_SYSRB3PC is written, this bit is asserted automatically by hardware, and is de-asserted when SRAM power change procedure is finished. Note 1: This bit is not retained when D1 power is turned off.
    0=System SRAM bank 3 power change finished; 1=System SRAM bank 3 power changing. The PMC_SYSRB0PC write operations are ignored
  [1:0] SRAM0PMS — System SRAM0 In Bank3 Power Mode Select (Write Protect). This field can control SRAM0 in bank3 (8k) power mode for range 0x2030_0000 - 0x2030_1FFF. Note 1: Power shut down mode can get least leakage, but don't guarantee the retention of SRAM data. Note 2: This bit is write protected. Refer to the SYS_REGLCTL register. Note 3: Write operation is ignored when PCBUSY is 1. Note 4: If system enter Power-down mode and D1PGEN(PMC_PWRCTL[1]) is set to 1, This SRAM is auto set to power shut down mode by hardware. Note 5: These bits are not retained when D1 power is turned off.
    0=System SRAM0 in bank3 is normal mode; 1=System SRAM0 in bank3 is retention mode; 2=System SRAM0 in bank3 is power shut down mode
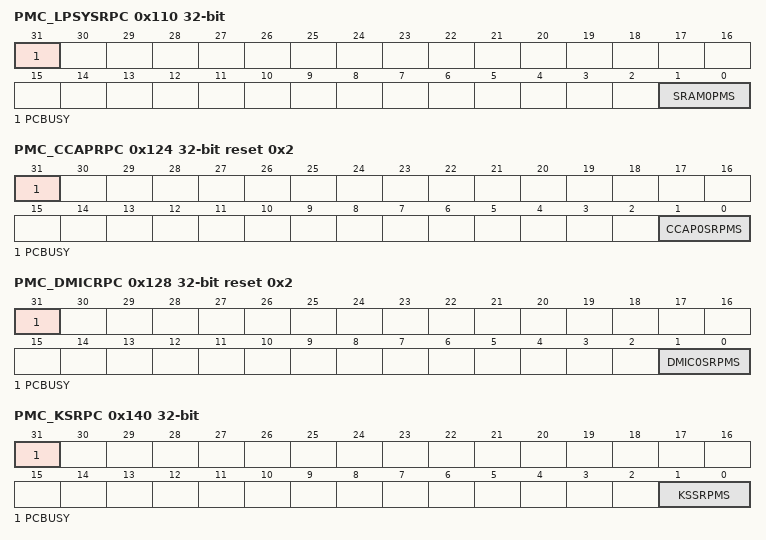
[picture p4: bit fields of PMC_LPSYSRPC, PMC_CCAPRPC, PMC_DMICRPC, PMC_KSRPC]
0x110 PMC_LPSYSRPC — Low Power Domain System SRAM Power Mode Control Register
  [31] PCBUSY ro — Power Changing Busy Flag (Read Only). If PMC_LPSYSRPC is written, this bit is asserted automatically by hardware, and is de-asserted when SRAM power change procedure is finished. Note 1: This bit is not retained when D3 power is turned off.
    0=Low power domain SRAM bank 3 power change finished; 1=Low power domain power changing. The PMC_SYSLPRPC write operations are ignored
  [1:0] SRAM0PMS — Low Power Domain SRAM0 Power Mode Select (Write Protect). This field can control SRAM0 (8k) power mode for range 0x2031_0000 - 0x2031_0FFF. Note 1: Power shut down mode can get least leakage, but don't guarantee the retention of SRAM data. Note 2: This bit is write protected. Refer to the SYS_REGLCTL register. Note 3: Write operation is ignored when PCBUSY is 1. Note 4: If system enter Power-down mode and D3PGEN(PMC_PWRCTL[3]) is set to 1, This SRAM is auto set to power shut down mode by hardware. Note 5: These bits are not retained when D3 power is turned off.
    0=System SRAM0 in low power domain is normal mode; 1=System SRAM0 in low power domain is retention mode; 2=System SRAM0 in low power domain is power shut down mode
0x124 PMC_CCAPRPC reset 0x2 — CCAP SRAM Power Mode Control Register
  [31] PCBUSY ro — Power Changing Busy Flag (Read Only). If PMC_CCAPRPC is written, this bit is asserted automatically by hardware, and is de-asserted when SRAM power change procedure is finished.
    0=CCAP SRAM power change finished; 1=CCAP SRAM power changing. The PMC_CCAPRPC write operations are ignored
  [1:0] CCAP0SRPMS — CCAP0 SRAM Power Mode Select (Write Protect). This field can control CCAP0 SRAM power mode. Note 1: Power shut down mode can get least leakage, but don't guarantee the retention of SRAM data. Note 2: This bit is write protected. Refer to the SYS_REGLCTL register. Note 3: Write operation is ignored when PCBUSY is 1. Note 4: These bits are not retained when D2 power is turned off. Note 5: This field only reset by POR reset.
    0=CCAP0 SRAM is normal mode; 1=CCAP0 SRAM is retention mode; 2=CCAP0 SRAM is power shut down mode
0x128 PMC_DMICRPC reset 0x2 — DMIC SRAM Power Mode Control Register
  [31] PCBUSY ro — Power Changing Busy Flag (Read Only). If PMC_DMICRPC is written, this bit is asserted automatically by hardware, and is de-asserted when SRAM power change procedure is finished.
    0=DMIC SRAM power change finished; 1=DMIC SRAM power changing. The PMC_DMICRPC write operations are ignored
  [1:0] DMIC0SRPMS — DMIC0 SRAM Power Mode Select (Write Protect). This field can control DMIC0 SRAM power mode. Note 1: Power shut down mode can get least leakage, but don't guarantee the retention of SRAM data. Note 2: This bit is write protected. Refer to the SYS_REGLCTL register. Note 3: Write operation is ignored when PCBUSY is 1. Note 4: These bits are not retained when D2 power is turned off. Note 5: This field only reset by POR reset.
    0=DMIC0 SRAM is normal mode; 1=DMIC0 SRAM is retention mode; 2=DMIC0 SRAM is power shut down mode
0x140 PMC_KSRPC — KS SRAM Power Mode Control Register
  [31] PCBUSY ro — Power Changing Busy Flag (Read Only). If PMC_KSRPC is written, this bit is asserted automatically by hardware, and is de-asserted when SRAM power change procedure is finished.
    0=KS SRAM power change finished; 1=KS SRAM power changing. The PMC_KSRPC write operations are ignored
  [1:0] KSSRPMS — KS SRAM Power Mode Select (Write Protect). This field can control KS0 SRAM power mode. Note 1: Power shut down mode can get least leakage, but don't guarantee the retention of SRAM data. Note 2: This bit is write protected. Refer to the SYS_REGLCTL register. Note 3: Write operation is ignored when PCBUSY is 1. Note 4: If system enter Power-down mode and D3PGEN(PMC_PWRCTL[3]) is set to 1, This SRAM is auto set to power shut down mode by hardware. Note 5: These bits are not retained when D3 power is turned off. Note 6: This field only reset by POR reset.
    0=KS SRAM is normal mode; 1=KS SRAM is retention mode; 2=KS SRAM is power shut down mode
